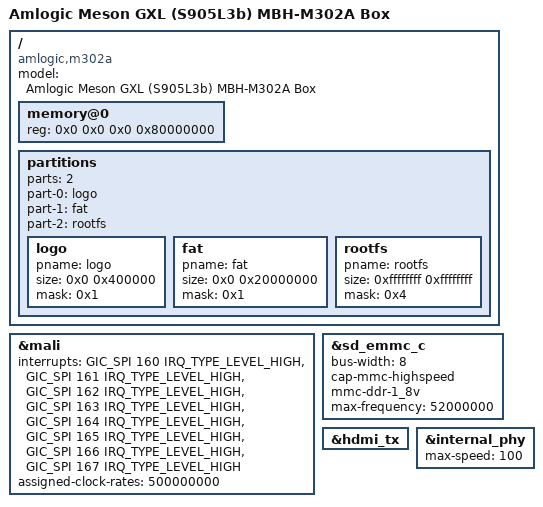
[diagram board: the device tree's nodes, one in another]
// SPDX-License-Identifier: (GPL-2.0+ OR MIT)
/*
 * Copyright (c) 2016 Endless Computers, Inc.
 * Author: Carlo Caione <carlo@endlessm.com>
 */

/dts-v1/;

#include "meson-gxl-s905w-p281.dts"

/ {
	compatible = "amlogic,m302a", "amlogic,s905w", "amlogic,meson-gxl";
	model = "Amlogic Meson GXL (S905L3b) MBH-M302A Box";
	
	memory@0 {
		device_type = "memory";
		reg = <0x0 0x0 0x0 0x80000000>;
	};

	partitions {
		parts = <2>;
		part-0 = <&logo>;
		part-1 = <&fat>;
		part-2 = <&rootfs>;
		logo:logo {
			pname = "logo";
			size = <0x0 0x400000>;
			mask = <0x1>;
		};
		fat:fat {
			pname = "fat";
			size = <0x0 0x20000000>;
			mask = <0x1>;
		};

		rootfs:rootfs {
			pname = "rootfs";
			size = <0xffffffff 0xffffffff>;
			mask = <0x4>;
		};
	};
};

// the gpu in the S905L2 has one pp core less
// (i.e. only two in total) than the one in the other S905X/W

&mali {
	interrupts = <GIC_SPI 160 IRQ_TYPE_LEVEL_HIGH>,
		<GIC_SPI 161 IRQ_TYPE_LEVEL_HIGH>,
		<GIC_SPI 162 IRQ_TYPE_LEVEL_HIGH>,
		<GIC_SPI 163 IRQ_TYPE_LEVEL_HIGH>,
		<GIC_SPI 164 IRQ_TYPE_LEVEL_HIGH>,
		<GIC_SPI 165 IRQ_TYPE_LEVEL_HIGH>,
		<GIC_SPI 166 IRQ_TYPE_LEVEL_HIGH>,
		<GIC_SPI 167 IRQ_TYPE_LEVEL_HIGH>;
	interrupt-names = "gp", "gpmmu", "pp", "pmu","pp0", "ppmmu0", "pp1", "ppmmu1";
	assigned-clock-rates = <500000000>;
};

&sd_emmc_c {
	status = "okay";
	bus-width = <8>;
	cap-mmc-highspeed;
	mmc-ddr-1_8v;
	/delete-property/ mmc-hs200-1_8v;
	max-frequency = <52000000>;
};

&hdmi_tx {
	status="okay";
};

&internal_phy {
	max-speed = <100>;
};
